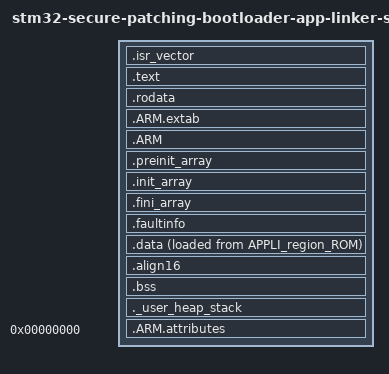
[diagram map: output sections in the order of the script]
/* This is a linker script for the SECTIONS group that is suitable
 * for most applications on most most targets not using QSPI or 
 * multisegment.
 *
 * This requires target/application-specific preamble in the project's
 * linker script as outlined in the README.md.
 *
 * To use, add the following where the SECTIONS tag would normally go:
 *
 * INCLUDE sbsfu_app_linker_sections.ld
 *
 */


/* Define output sections */
SECTIONS
{
  /* The startup code goes first into FLASH */
  .isr_vector :
  {
    . = ALIGN(8);
    KEEP(*(.isr_vector)) /* Startup code */
    FILL(0);
    . = ORIGIN(ISR_VECTOR) + LENGTH(ISR_VECTOR) - 1;
    BYTE(0)
    . = ALIGN(8);
  } >ISR_VECTOR

  /* The program code and other data goes into FLASH */
  .text :
  {
    . = ALIGN(8);
    *(.text)           /* .text sections (code) */
    *(.text*)          /* .text* sections (code) */
    *(.glue_7)         /* glue arm to thumb code */
    *(.glue_7t)        /* glue thumb to arm code */
    *(.eh_frame)

    KEEP (*(.init))
    KEEP (*(.fini))

    . = ALIGN(8);
    _etext = .;        /* define a global symbol at end of code */
  } >APPLI_region_ROM

  /* Constant data goes into FLASH */
  .rodata :
  {
    . = ALIGN(8);
    *(.rodata)         /* .rodata sections (constants, strings, etc.) */
    *(.rodata*)        /* .rodata* sections (constants, strings, etc.) */
    . = ALIGN(8);
  } >APPLI_region_ROM

  .ARM.extab   :
  {
  . = ALIGN(8);
  *(.ARM.extab* .gnu.linkonce.armextab.*)
  . = ALIGN(8);
  } >APPLI_region_ROM
  .ARM : {
	. = ALIGN(8);
    __exidx_start = .;
    *(.ARM.exidx*)
    __exidx_end = .;
	. = ALIGN(8);
  } >APPLI_region_ROM

  .preinit_array     :
  {
	. = ALIGN(8);
    PROVIDE_HIDDEN (__preinit_array_start = .);
    KEEP (*(.preinit_array*))
    PROVIDE_HIDDEN (__preinit_array_end = .);
	. = ALIGN(8);
  } >APPLI_region_ROM

  .init_array :
  {
	. = ALIGN(8);
    PROVIDE_HIDDEN (__init_array_start = .);
    KEEP (*(SORT(.init_array.*)))
    KEEP (*(.init_array*))
    PROVIDE_HIDDEN (__init_array_end = .);
	. = ALIGN(8);
  } >APPLI_region_ROM
  .fini_array :
  {
	. = ALIGN(8);
    PROVIDE_HIDDEN (__fini_array_start = .);
    KEEP (*(SORT(.fini_array.*)))
    KEEP (*(.fini_array*))
    PROVIDE_HIDDEN (__fini_array_end = .);
	. = ALIGN(8);
  } >APPLI_region_ROM

  /* Section used to store fault information across reboots
   */
  .faultinfo (NOLOAD):
  {
    . = ALIGN(4);
    _start_of_faultinfo = .;
    *(.faultinfo)
    *(.faultinfo.*)
    . = . + 1;
    . = ALIGN(64);
    _end_of_faultinfo = .;
  } >APPLI_region_RAM

  /* used by the startup to initialize data */
  _sidata = LOADADDR(.data);

  /* Initialized data sections goes into RAM, load LMA copy after code */
  .data :
  {
    . = ALIGN(8);
    _sdata = .;        /* create a global symbol at data start */
    *(.ramfunc*)       /* Functions setup to run in RAM */
    *(.data)           /* .data sections */
    *(.data*)          /* .data* sections */

    . = ALIGN(8);
    _edata = .;        /* define a global symbol at data end */
  } >APPLI_region_RAM AT>APPLI_region_ROM

   /* Extra ROM section (last one) to make sure the binary size is a multiple of the AES block size (16 bytes) */
  .align16 :
  {
    . = . + 1;         /* _edata=. is aligned on 8 bytes so could be aligned on 16 bytes: add 1 byte gap */
    . = ALIGN(16) - 1; /* increment the location counter until next 16 bytes aligned address (-1 byte)   */
    BYTE(0);           /* allocate 1 byte (value is 0) to be a multiple of 16 bytes                      */
  } > APPLI_region_ROM

  /* Uninitialized data section */
  . = ALIGN(4);
  .bss :
  {
    /* This is used by the startup in order to initialize the .bss secion */
    _sbss = .;         /* define a global symbol at bss start */
    __bss_start__ = _sbss;
    *(.bss)
    *(.bss*)
    *(COMMON)
    . = ALIGN(4);
    /* insert bss guard word at the end of the section */
    __bss_guard = .;
    . = . + 4;
    /* end bss guard word */
    _ebss = .;         /* define a global symbol at bss end */
    __bss_end__ = _ebss;
  } >APPLI_region_RAM

  /* User_heap_stack section, used to check that there is enough RAM left */
  ._user_heap_stack :
  {
    . = ALIGN(8);
    PROVIDE ( end = . );
    PROVIDE ( _end = . );
    . = . + _Min_Heap_Size;
    . = . + _Min_Stack_Size;
    . = ALIGN(8);
  } >APPLI_region_RAM



  /* Remove information from the standard libraries */
  /DISCARD/ :
  {
    libc.a ( * )
    libm.a ( * )
    libgcc.a ( * )
  }

  .ARM.attributes 0 : { *(.ARM.attributes) }
}
